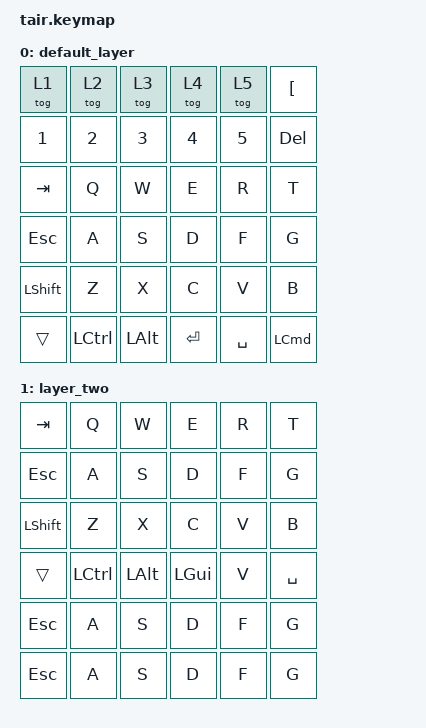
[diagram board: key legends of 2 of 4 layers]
#include <behaviors.dtsi>
#include <dt-bindings/zmk/keys.h>
#include <dt-bindings/zmk/bt.h>

/ {
    keymap {
        compatible = "zmk,keymap";

        default_layer {
            // -----------------------------------------------------------------------------------------
            // |  TAB  |  Q   |  W   |  E   |  R   |  T   |   
            // |  ESC  |  A   |  S   |  D   |  F   |  G   |   
            // | SHIFT |  Z   |  X   |  C   |  V   |  B   |   
            // | LCTL | LALT | LGUI | LOWR |   SPACE  |f|
            // | LCTL | LALT | LGUI | LOWR |   SPACE  |f|
            // | LCTL | LALT | LGUI   	   	   | LOWR | SPACE | f |

            bindings = <    
                &tog 1 &tog 2  &tog 3  &tog 4  &tog 5  &kp LBKT 
	    	&kp N1  &kp N2  &kp N3  &kp N4  &kp N5  &kp DEL
                &kp TAB  &kp Q  &kp W  &kp E  &kp R  &kp T  
                &kp ESC  &kp A  &kp S  &kp D  &kp F  &kp G 
                &kp LSHFT &kp Z &kp X  &kp C &kp V &kp B
                &trans   &kp LCTL &kp LALT &kp RETURN  &kp SPACE &kp LCMD
                        >;
        };

        layer_two {
            // -----------------------------------------------------------------------------------------
            // |  Y  |  U   |  I   |  O   |  P   |  T   |   
            // |  H  |  J   |  K   |  L   |  ;   |  "   |   
            // | SHIFT |  Z   |  X   |  C   |  V   |  B   |   
            // | LCTL | LALT | LGUI | LOWR |   SPACE  |f|
            // | LCTL | LALT | LGUI | LOWR |   SPACE  |f|
            // | LCTL | LALT | LGUI   	   	   | LOWR | SPACE | f |

            bindings = <
                &kp TAB  &kp Q  &kp W  &kp E  &kp R  &kp T  
                &kp ESC  &kp A  &kp S  &kp D  &kp F  &kp G 
                &kp LSHFT &kp Z    &kp X &kp C &kp V &kp B
                &trans   &kp LCTL &kp LALT &kp LGUI &kp V &kp SPACE
                &kp ESC  &kp A  &kp S  &kp D  &kp F  &kp G 
                &kp ESC  &kp A  &kp S  &kp D  &kp F  &kp G 
            >;
        };


	layer_three {
            // -----------------------------------------------------------------------------------------
            // |  TAB  |  Q   |  W   |  E   |  R   |  T   |   Y   |  U    |  I   |  O   |   P   | BSPC  |
            // |  ESC  |  A   |  S   |  D   |  F   |  G   |   H   |  J    |  K   |  L   |   ;   |  '    |
            // | SHIFT |  Z   |  X   |  C   |  V   |  B   |   N   |  M    |  ,   |  .   |   /   |  RET  |
            // |       | LCTL | LALT | LGUI | LOWR |     SPACE    |  RAIS | LARW | DARW | UARW  |  RARW |
            bindings = <
                &kp TAB  &kp Q    &kp W &kp E &kp R &kp T  
                &kp ESC  &kp A    &kp S &kp D &kp F &kp G 
                &kp LSHFT &kp Z    &kp X &kp C &kp V &kp B
                &trans   &kp LCTL &kp LALT &kp LGUI &kp V &kp SPACE
            >;
        };

        layer_four {
            // -----------------------------------------------------------------------------------------
            // |  TAB  |  Q   |  W   |  E   |  R   |  T   |   Y   |  U    |  I   |  O   |   P   | BSPC  |
            // |  ESC  |  A   |  S   |  D   |  F   |  G   |   H   |  J    |  K   |  L   |   ;   |  '    |
            // | SHIFT |  Z   |  X   |  C   |  V   |  B   |   N   |  M    |  ,   |  .   |   /   |  RET  |
            // |       | LCTL | LALT | LGUI | LOWR |     SPACE    |  RAIS | LARW | DARW | UARW  |  RARW |
            bindings = <
                &kp TAB  &kp Q    &kp W &kp E &kp R &kp T  
                &kp ESC  &kp A    &kp S &kp D &kp F &kp G 
                &kp LSHFT &kp Z    &kp X &kp C &kp V &kp B
                &trans   &kp LCTL &kp LALT &kp LGUI &kp V &kp SPACE
            >;
        };


    };
};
